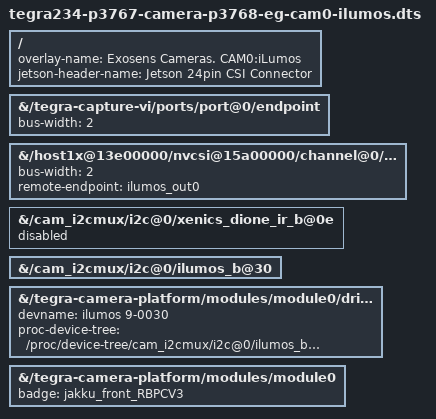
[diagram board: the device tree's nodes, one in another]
// SPDX-License-Identifier: GPL-2.0-only

/dts-v1/;
/plugin/;

#include <dt-common/jetson/tegra234-p3767-0000-common.h>

/ {
	overlay-name = "Exosens Cameras. CAM0:iLumos";
	jetson-header-name = "Jetson 24pin CSI Connector";
	compatible = JETSON_COMPATIBLE_P3768;

	fragment@00 {
		target-path = "/tegra-capture-vi/ports/port@0/endpoint";
		__overlay__ {
			bus-width=<2>;
		};
	};

	fragment@1 {
		target-path = "/host1x@13e00000/nvcsi@15a00000/channel@0/ports/port@0/endpoint@0";
		__overlay__ {
			bus-width=<2>;
			remote-endpoint = <&ilumos_out0>;
		};
	};

   // Disable Dione cameras
	fragment@2 {
		target-path = "/cam_i2cmux/i2c@0/xenics_dione_ir_b@0e";
		__overlay__ {
         status = "disabled";
		};
	};

	// Enable iLumos
	fragment@3 {
		target-path = "/cam_i2cmux/i2c@0/ilumos_b@30";
		__overlay__ {
         status = "okay";
		};
	};

	fragment@6 {
		target-path = "/tegra-camera-platform/modules/module0/drivernode0";
		__overlay__ {
			devname = "ilumos 9-0030";
			proc-device-tree = "/proc/device-tree/cam_i2cmux/i2c@0/ilumos_b@30";
		};
	};

	fragment@7 {
		target-path = "/tegra-camera-platform/modules/module0";
		__overlay__ {
			badge = "jakku_front_RBPCV3";
		};
	};


};
